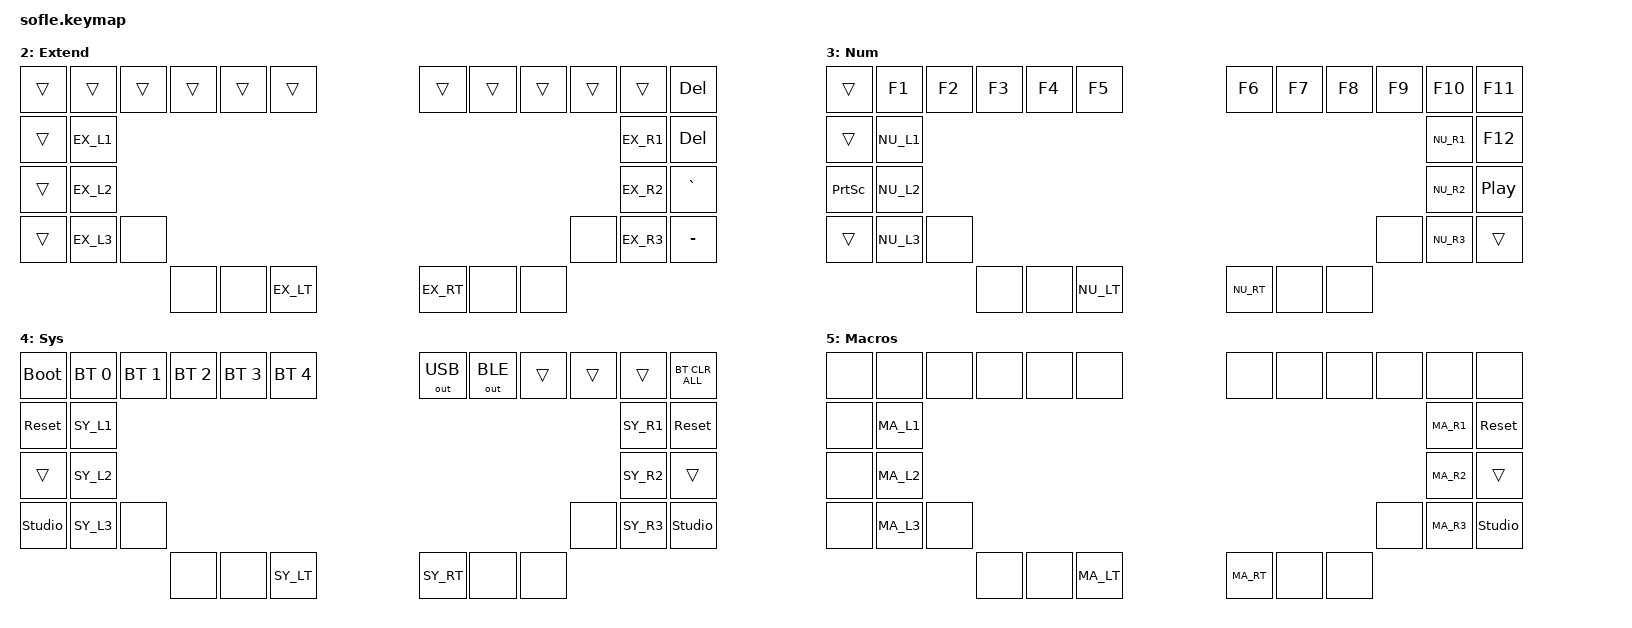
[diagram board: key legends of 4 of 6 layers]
/*
 * Sofle — 60 positions, 58 keys + 2 encoder presses.
 * Layout lives in config/shared/core36.h and is shared with every other board.
 * This file only supplies what sits AROUND the core: number row, outer pinky
 * columns, encoder presses and the two outer thumbs per side.
 *
 * Position map (&none = 42, 43, 50, 51, 58, 59):
 *   0  1  2  3  4  5                 6  7  8  9 10 11
 *  12 13 14 15 16 17                18 19 20 21 22 23
 *  24 25 26 27 28 29                30 31 32 33 34 35
 *  36 37 38 39 40 41 [42]      [43] 44 45 46 47 48 49
 *       [50] [51] 52 53 54    55 56 57 [58] [59]
 */

#include <behaviors.dtsi>
#include <dt-bindings/zmk/keys.h>
#include <dt-bindings/zmk/bt.h>
#include <dt-bindings/zmk/outputs.h>

#include "shared/layers.h"

#define KEYS_L 0 1 2 3 4 5 12 13 14 15 16 17 24 25 26 27 28 29 36 37 38 39 40 41
#define KEYS_R 6 7 8 9 10 11 18 19 20 21 22 23 30 31 32 33 34 35 44 45 46 47 48 49
#define THUMBS 52 53 54 55 56 57

#include "shared/behaviors.dtsi"
#include "shared/core36.h"
#include "shared/macros_combos.dtsi"

/ {
    macros {
        
    };

    combos {
        compatible = "zmk,combos";

        /* the two top corners - swaps base layout either way */
        combo_to_qwerty {
            timeout-ms = <75>;
            key-positions = <0 11>;
            bindings = <&to QWE>;
            layers = <BASE>;
        };
        combo_to_graphite {
            timeout-ms = <75>;
            key-positions = <0 11>;
            bindings = <&to BASE>;
            layers = <QWE>;
        };

        /* macros_combos */
        combo_main_pw {
            timeout-ms = <60>;
            key-positions = <1>;
            bindings = <&main_pw>;
            layers = <MACRO>;
        };
        combo_console_pw {
            timeout-ms = <60>;
            key-positions = <2>;
            bindings = <&console_pw>;
            layers = <MACRO>;
        };
        combo_sudo_pw {
            timeout-ms = <60>;
            key-positions = <3>;
            bindings = <&sudo_pw>;
            layers = <MACRO>;
        };
        combo_admin_pw {
            timeout-ms = <60>;
            key-positions = <4>;
            bindings = <&admin_pw>;
            layers = <MACRO>;
        };
        combo_fms_login {
            timeout-ms = <60>;
            key-positions = <5>;
            bindings = <&fms_login>;
            layers = <MACRO>;
        };
        combo_cd_fix {
            timeout-ms = <60>;
            key-positions = <6>;
            bindings = <&cd_fix>;
            layers = <MACRO>;
        };
    };

    keymap {
        compatible = "zmk,keymap";

        base_layer {
            display-name = "Graphite";
            bindings = <
&trans         &kp N1 &kp N2 &kp N3 &kp N4 &kp N5                   &kp N6 &kp N7 &kp N8 &kp N9 &kp N0 &trans
&lt UTIL TAB   GR_L1                                                GR_R1                        &kp SEMI
&mt LGUI ESC   GR_L2                                                GR_R2                        &gcm
&smsh          GR_L3                        &none          &none    GR_R3                        &kp RSHFT
                       &none  &none  GR_LT                          GR_RT  &none  &none
            >;
        };

        qwerty_layer {
            display-name = "QWERTY";
            bindings = <
&trans         &kp N1 &kp N2 &kp N3 &kp N4 &kp N5                   &kp N6 &kp N7 &kp N8 &kp N9 &kp N0 &trans
&lt UTIL TAB   QW_L1                                                QW_R1                              &kp BSLH
&mt LGUI ESC   QW_L2                                                QW_R2                              &kp APOS
&smsh          QW_L3                        &none          &none    QW_R3                              &kp EQUAL
                       &none  &none  QW_LT                          QW_RT  &none  &none
            >;
        };

        ext_layer {
            display-name = "Extend";
            bindings = <
&trans     &trans &trans &trans &trans &trans                        &trans &trans &trans &trans &trans &kp DEL
&trans     EX_L1                                                     EX_R1                             &kp DEL
&trans     EX_L2                                                     EX_R2                             &kp GRAVE
&trans     EX_L3                            &none          &none     EX_R3                             &kp MINUS
                       &none  &none  EX_LT                           EX_RT  &none  &none
            >;
        };

        num_layer {
            display-name = "Num";
            bindings = <
&trans     &kp F1 &kp F2 &kp F3 &kp F4 &kp F5                        &kp F6 &kp F7 &kp F8 &kp F9 &kp F10 &kp F11
&trans     NU_L1                                                     NU_R1                              &kp F12
&kp PSCRN  NU_L2                                                     NU_R2                              &kp C_PP
&trans     NU_L3                            &none          &none     NU_R3                              &trans
                       &none  &none  NU_LT                           NU_RT  &none  &none
            >;
        };

        sys_layer {
            display-name = "Sys";
            bindings = <
&bootloader     &bt BT_SEL 0 &bt BT_SEL 1 &bt BT_SEL 2 &bt BT_SEL 3 &bt BT_SEL 4      &out OUT_USB &out OUT_BLE &trans &trans &trans &bt BT_CLR_ALL
&sys_reset      SY_L1                                                                 SY_R1                                   &sys_reset
&trans          SY_L2                                                                 SY_R2                                   &trans
&studio_unlock  SY_L3                                   &none          &none          SY_R3                                   &studio_unlock
                                   &none  &none  SY_LT                                SY_RT  &none  &none
            >;
        };

        mac_layer {
            display-name = "Macros";
            bindings = <
&none     &none &none &none &none &none                                               &none &none &none &none &none           &none
&none     MA_L1                                                                       MA_R1                                   &sys_reset
&none     MA_L2                                                                       MA_R2                                   &trans
&none     MA_L3                                         &none          &none          MA_R3                                   &studio_unlock
                                   &none  &none  MA_LT                                MA_RT  &none  &none
            >;
        };

        extra_1 { status = "reserved"; };
        extra_2 { status = "reserved"; };
    };
};

/*
        mac_layer {
            display-name = "Macros";
            bindings = <
&none     &none &none &none &none &none                                               &none &none &none &none &none           &none
&none     SY_L1                                                                       SY_R1                                   &sys_reset
&none     SY_L2                                                                       SY_R2                                   &trans
&none     SY_L3                                         &none          &none          SY_R3                                   &studio_unlock
                                   &none  &none  SY_LT                                SY_RT  &none  &none
            >;
        };
*/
